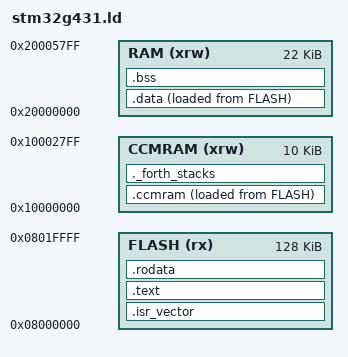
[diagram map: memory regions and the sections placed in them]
/* stm32g431kb linker script */
/* NUCLEO-32 */

/* Entry Point */
ENTRY(Reset_Handler)


_rStack_Size = 0x200; /* size of return stack */
/* Highest address of the user mode stack */
_rstack = 0x10002800;    /* end of CCRAM growind down */
_dStack_Size = 0x200; /* size of data stack */
_dstack = 0x10002400; /* growing up */
/* Specify the memory areas */
MEMORY
{
FLASH (rx)     : ORIGIN = 0x08000000, LENGTH = 128K
RAM (xrw)      : ORIGIN = 0x20000000, LENGTH = 22K
CCMRAM (xrw)   : ORIGIN = 0x10000000, LENGTH = 10K
}

/* Define output sections */
SECTIONS
{
  /* The startup code goes first into FLASH */
  .isr_vector :
  {
    . = ALIGN(4);
    KEEP(*(.isr_vector)) /* Startup code */
    . = ALIGN(4);
  } >FLASH

  /* The program code and other data goes into FLASH */
  .text :
  {
    . = ALIGN(4);
    *(.text)           /* .text sections (code) */
    *(.text*)          /* .text* sections (code) */

    KEEP (*(.init))
    KEEP (*(.fini))

    . = ALIGN(4);
    _etext = .;        /* define a global symbols at end of code */
  } >FLASH

  /* Constant data goes into FLASH */
  .rodata :
  {
    . = ALIGN(4);
    *(.rodata)         /* .rodata sections (constants, strings, etc.) */
    *(.rodata*)        /* .rodata* sections (constants, strings, etc.) */
    . = ALIGN(4);
  } >FLASH


  /* used by the startup to initialize data */
  _sidata = LOADADDR(.data);

  /* Initialized data sections goes into RAM, load LMA copy after code */
  .data : 
  {
    . = ALIGN(4);
    _sdata = .;        /* create a global symbol at data start */
    *(.data)           /* .data sections */
    *(.data*)          /* .data* sections */

    . = ALIGN(4);
    _edata = .;        /* define a global symbol at data end */
  } >RAM AT> FLASH

  _siccmram = LOADADDR(.ccmram);

  /* CCM-RAM section 
  * 
  * IMPORTANT NOTE! 
  * If initialized variables will be placed in this section,
  * the startup code needs to be modified to copy the init-values.  
  */
  .ccmram :
  {
    . = ALIGN(4);
    _sccmram = .;       /* create a global symbol at ccmram start */
    *(.ccmram)
    *(.ccmram*)
    
    . = ALIGN(4);
    _eccmram = .;       /* create a global symbol at ccmram end */
  } >CCMRAM AT> FLASH

  
  /* Uninitialized data section */
  . = ALIGN(4);
  .bss :
  {
    /* This is used by the startup in order to initialize the .bss secion */
    _sbss = .;         /* define a global symbol at bss start */
    __bss_start__ = _sbss;
    *(.bss)
    *(.bss*)
    *(COMMON)

    . = ALIGN(4);
    _ebss = .;         /* define a global symbol at bss end */
    __bss_end__ = _ebss;
  } >RAM

  /* User_heap_stack section, used to check that there is enough RAM left */
  ._forth_stacks :
  {
    . = ALIGN(8);
    PROVIDE ( end = . );
    PROVIDE ( _end = . );
    . = . + _dStack_Size;
    . = . + _rStack_Size;
    . = ALIGN(8);
  } >CCMRAM

  
  .ARM.attributes 0 : { *(.ARM.attributes) } 
}
